# MSPM0L134X register map
Vendor: Texas Instruments; File version: This preliminary header file does not have a version number - build date: 2023-02-21 16:43:37
CPU: CM0 r0p1, little endian, MPU, no FPU, 3 interrupt priority bits
Registers are 32-bit, read-write, reset 0x0 unless marked. A register's access mark holds for its fields unless they carry their own. Offsets are from the block's base; [hi:lo] are bit positions; lines under a group give offsets from that group; {n}, {i} and the like mark numbered series.

## FLASHCTL — F65NW
Base 0x400CD000
0x1020 IIDX ro — Interrupt Index Register
  [0] IIDX_STAT — Indicates which interrupt has fired. 0x0 means no event pending. The priority order is fixed. On each read, only one interrupt is indicated. On a read, the current interrupt (highest priority) is automatically cleared by the hardware and the corresponding interrupt flags in the RIS and MIS are cleared as well. After a read from the CPU (not from the debug interface), the register must be updated with the next highest priority interrupt.
    0=IIDX_STAT_NO_INTR (NO_INTR); 1=IIDX_STAT_DONE (DONE)
0x1028 IMASK — Interrupt Mask Register
  [0] IMASK_DONE — Interrupt mask for DONE: 0: Interrupt is disabled in MIS register 1: Interrupt is enabled in MIS register
    0=IMASK_DONE_DISABLED (DISABLED); 1=IMASK_DONE_ENABLED (ENABLED)
0x1030 RIS ro — Raw Interrupt Status Register
  [0] RIS_DONE — NoWrapper operation completed. This interrupt bit is set by firmware or the corresponding bit in the ISET register. It is cleared by the corresponding bit in in the ICLR register or reading the IIDX register when this interrupt is the highest priority.
    0=RIS_DONE_CLR (CLR); 1=RIS_DONE_SET (SET)
0x1038 MIS ro — Masked Interrupt Status Register
  [0] MIS_DONE — NoWrapper operation completed. This masked interrupt bit reflects the bitwise AND of the corresponding RIS and IMASK bits.
    0=MIS_DONE_CLR (CLR); 1=MIS_DONE_SET (SET)
0x1040 ISET wo — Interrupt Set Register
  [0] ISET_DONE — 0: No effect 1: Set the DONE interrupt in the RIS register
    0=ISET_DONE_NO_EFFECT (NO_EFFECT); 1=ISET_DONE_SET (SET)
0x1048 ICLR wo — Interrupt Clear Register
  [0] ICLR_DONE — 0: No effect 1: Clear the DONE interrupt in the RIS register
    0=ICLR_DONE_NO_EFFECT (NO_EFFECT); 1=ICLR_DONE_CLR (CLR)
0x10E0 EVT_MODE ro — Event Mode
  [1:0] EVT_MODE_INT0_CFG — Event line mode select for peripheral event
    0=EVT_MODE_INT0_CFG_DISABLE (DISABLE); 1=EVT_MODE_INT0_CFG_SOFTWARE (SOFTWARE); 2=EVT_MODE_INT0_CFG_HARDWARE (HARDWARE)
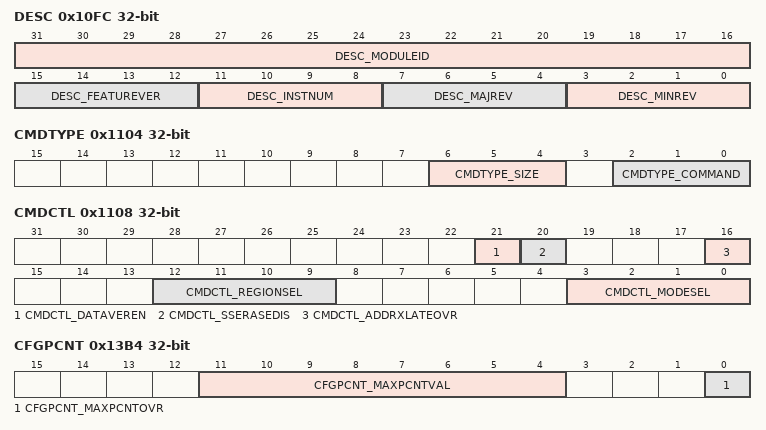
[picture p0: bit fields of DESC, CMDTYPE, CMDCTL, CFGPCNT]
0x10FC DESC ro — Hardware Version Description Register
  [31:16] DESC_MODULEID — Module ID
  [15:12] DESC_FEATUREVER — Feature set
  [11:8] DESC_INSTNUM — Instance number
  [7:4] DESC_MAJREV — Major Revision
  [3:0] DESC_MINREV — Minor Revision
0x1100 CMDEXEC — Command Execute Register
  [0] CMDEXEC_VAL — Command Execute value Initiates execution of the command specified in the CMDTYPE register.
    0=CMDEXEC_VAL_NOEXECUTE (NOEXECUTE); 1=CMDEXEC_VAL_EXECUTE (EXECUTE)
0x1104 CMDTYPE — Command Type Register
  [6:4] CMDTYPE_SIZE — Command size
    0=CMDTYPE_SIZE_ONEWORD (ONEWORD); 1=CMDTYPE_SIZE_TWOWORD (TWOWORD); 2=CMDTYPE_SIZE_FOURWORD (FOURWORD); 3=CMDTYPE_SIZE_EIGHTWORD (EIGHTWORD); 4=CMDTYPE_SIZE_SECTOR (SECTOR); 5=CMDTYPE_SIZE_BANK (BANK)
  [2:0] CMDTYPE_COMMAND — Command type
    0=CMDTYPE_COMMAND_NOOP (NOOP); 1=CMDTYPE_COMMAND_PROGRAM (PROGRAM); 2=CMDTYPE_COMMAND_ERASE (ERASE); 3=CMDTYPE_COMMAND_READVERIFY (READVERIFY); 4=CMDTYPE_COMMAND_MODECHANGE (MODECHANGE); 5=CMDTYPE_COMMAND_CLEARSTATUS (CLEARSTATUS); 6=CMDTYPE_COMMAND_BLANKVERIFY (BLANKVERIFY)
0x1108 CMDCTL — Command Control Register
  [21] CMDCTL_DATAVEREN — Enable invalid data verify. This checks for 0->1 transitions in the memory when a program operation is initiated. If such a transition is found, the program will fail with an error without doing any programming.
    0=CMDCTL_DATAVEREN_DISABLE (DISABLE); 1=CMDCTL_DATAVEREN_ENABLE (ENABLE)
  [20] CMDCTL_SSERASEDIS — Disable Stair-Step Erase. If set, the default VHV trim voltage setting will be used for all erase pulses. By default, this bit is reset, meaning that the VHV voltage will be stepped during successive erase pulses. The step count, step voltage, begin and end voltages are all hard-wired.
    0=CMDCTL_SSERASEDIS_ENABLE (ENABLE); 1=CMDCTL_SSERASEDIS_DISABLE (DISABLE)
  [16] CMDCTL_ADDRXLATEOVR — Override hardware address translation of address in CMDADDR from a system address to a bank address and bank ID. Use data written to CMDADDR directly as the bank address. Use the value written to CMDCTL.BANKSEL directly as the bank ID. Use the value written to CMDCTL.REGIONSEL directly as the region ID.
    0=CMDCTL_ADDRXLATEOVR_NOOVERRIDE (NOOVERRIDE); 1=CMDCTL_ADDRXLATEOVR_OVERRIDE (OVERRIDE)
  [12:9] CMDCTL_REGIONSEL — Bank Region A specific region ID can be written to this field to indicate to which region an operation should be applied if CMDCTL.ADDRXLATEOVR is set.
    1=CMDCTL_REGIONSEL_MAIN (MAIN); 2=CMDCTL_REGIONSEL_NONMAIN (NONMAIN); 4=CMDCTL_REGIONSEL_TRIM (TRIM); 8=CMDCTL_REGIONSEL_ENGR (ENGR)
  [3:0] CMDCTL_MODESEL — Mode This field is only used for the Mode Change command type. Otherwise, bank and pump modes are set automaticlly via the NW hardware.
    0=CMDCTL_MODESEL_READ (READ); 2=CMDCTL_MODESEL_RDMARG0 (RDMARG0); 4=CMDCTL_MODESEL_RDMARG1 (RDMARG1); 6=CMDCTL_MODESEL_RDMARG0B (RDMARG0B); 7=CMDCTL_MODESEL_RDMARG1B (RDMARG1B); 9=CMDCTL_MODESEL_PGMVER (PGMVER); 10=CMDCTL_MODESEL_PGMSW (PGMSW); 11=CMDCTL_MODESEL_ERASEVER (ERASEVER); 12=CMDCTL_MODESEL_ERASESECT (ERASESECT); 14=CMDCTL_MODESEL_PGMMW (PGMMW); 15=CMDCTL_MODESEL_ERASEBNK (ERASEBNK)
0x1120 CMDADDR — Command Address Register
  [31:0] CMDADDR_VAL — Address value
0x1124 CMDBYTEN — Command Program Byte Enable Register
  [7:0] CMDBYTEN_VAL — Command Byte Enable value. A 1-bit per flash word byte value is placed in this register.
0x1130 CMDDATA0 — Command Data Register 0
  [31:0] CMDDATA0_VAL — A 32-bit data value is placed in this field.
0x1134 CMDDATA1 — Command Data Register 1
  [31:0] CMDDATA1_VAL — A 32-bit data value is placed in this field.
0x11D0 CMDWEPROTA — Command Write Erase Protect A Register
  [31:0] CMDWEPROTA_VAL — Each bit protects 1 sector. bit [0]: When 1, sector 0 of the flash memory will be protected from program and erase. bit [1]: When 1, sector 1 of the flash memory will be protected from program and erase. : : bit [31]: When 1, sector 31 of the flash memory will be protected from program and erase.
0x11D4 CMDWEPROTB — Command Write Erase Protect B Register
  [3:0] CMDWEPROTB_VAL — Each bit protects a group of 8 sectors. When a bit is 1, the associated 8 sectors in the flash will be protected from program and erase. A maximum of 256 sectors can be protected with this register.
0x11D8 CMDWEPROTC — Command Write Erase Protect C Register
  [0] CMDWEPROTC_VAL — Each bit protects a group of 8 sectors. When a bit is 1, the associated 8 sectors in the flash will be protected from program and erase. Note that the sectors protected with this register start at sector 256 in the flash, where the sectors protected by the CMDWEPROTB register end.
0x1210 CMDWEPROTNM — Command Write Erase Protect Non-Main Register
  [0] CMDWEPROTNM_VAL — Each bit protects 1 sector. bit [0]: When 1, sector 0 of the non-main region will be protected from program and erase. bit [1]: When 1, sector 1 of the non-main region will be protected from program and erase. : : bit [31]: When 1, sector 31 of the non-main will be protected from program and erase.
0x1214 CMDWEPROTTR — Command Write Erase Protect Trim Register
  [0] CMDWEPROTTR_VAL — Each bit protects 1 sector. bit [0]: When 1, sector 0 of the engr region will be protected from program and erase. bit [1]: When 1, sector 1 of the engr region will be protected from program and erase. : : bit [31]: When 1, sector 31 of the engr region will be protected from program and erase.
0x1218 CMDWEPROTEN — Command Write Erase Protect Engr Register
  [1:0] CMDWEPROTEN_VAL — Each bit protects 1 sector. bit [0]: When 1, sector 0 of the engr region will be protected from program and erase. bit [1]: When 1, sector 1 of the engr region will be protected from program and erase. : : bit [31]: When 1, sector 31 of the engr region will be protected from program and erase.
0x13B0 CFGCMD — Command Configuration Register
  [3:0] CFGCMD_WAITSTATE — Wait State setting for program verify, erase verify and read verify
0x13B4 CFGPCNT — Pulse Counter Configuration Register
  [11:4] CFGPCNT_MAXPCNTVAL — Override maximum pulse counter with this value. If MAXPCNTOVR = 0, then this field is ignored. If MAXPCNTOVR = 1 and MAXERSPCNTOVR = 0, then this value will be used to override the max pulse count for both program and erase. Full max value will be {4'h0, MAXPCNTVAL} . If MAXPCNTOVR = 1 and MAXERSPCNTOVR = 1, then this value will be used to override the max pulse count for program only. Full max value will be {4'h0, MAXPCNTVAL}.
  [0] CFGPCNT_MAXPCNTOVR — Override hard-wired maximum pulse count. If MAXERSPCNTOVR is not set, then setting this value alone will override the max pulse count for both program and erase. If MAXERSPCNTOVR is set, then this bit will only control the max pulse count setting for program. By default, this bit is 0, and a hard-wired max pulse count is used.
    0=CFGPCNT_MAXPCNTOVR_DEFAULT (DEFAULT); 1=CFGPCNT_MAXPCNTOVR_OVERRIDE (OVERRIDE)
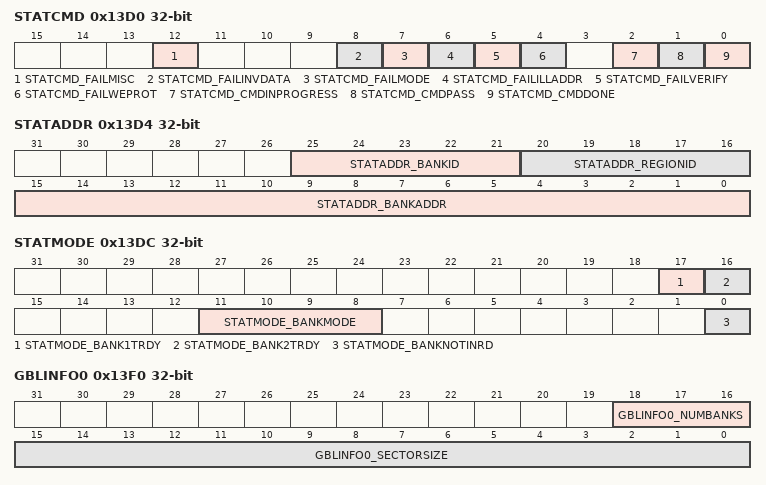
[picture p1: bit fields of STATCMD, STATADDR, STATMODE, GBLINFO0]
0x13D0 STATCMD ro — Command Status Register
  [12] STATCMD_FAILMISC — Command failed due to error other than write/erase protect violation or verify error. This is an extra bit in case a new failure mechanism is added which requires a status bit.
    0=STATCMD_FAILMISC_STATNOFAIL (STATNOFAIL); 1=STATCMD_FAILMISC_STATFAIL (STATFAIL)
  [8] STATCMD_FAILINVDATA — Program command failed because an attempt was made to program a stored 0 value to a 1.
    0=STATCMD_FAILINVDATA_STATNOFAIL (STATNOFAIL); 1=STATCMD_FAILINVDATA_STATFAIL (STATFAIL)
  [7] STATCMD_FAILMODE — Command failed because a bank has been set to a mode other than READ. Program and Erase commands cannot be initiated unless all banks are in READ mode.
    0=STATCMD_FAILMODE_STATNOFAIL (STATNOFAIL); 1=STATCMD_FAILMODE_STATFAIL (STATFAIL)
  [6] STATCMD_FAILILLADDR — Command failed due to the use of an illegal address
    0=STATCMD_FAILILLADDR_STATNOFAIL (STATNOFAIL); 1=STATCMD_FAILILLADDR_STATFAIL (STATFAIL)
  [5] STATCMD_FAILVERIFY — Command failed due to verify error
    0=STATCMD_FAILVERIFY_STATNOFAIL (STATNOFAIL); 1=STATCMD_FAILVERIFY_STATFAIL (STATFAIL)
  [4] STATCMD_FAILWEPROT — Command failed due to Write/Erase Protect Sector Violation
    0=STATCMD_FAILWEPROT_STATNOFAIL (STATNOFAIL); 1=STATCMD_FAILWEPROT_STATFAIL (STATFAIL)
  [2] STATCMD_CMDINPROGRESS — Command In Progress
    0=STATCMD_CMDINPROGRESS_STATCOMPLETE (STATCOMPLETE); 1=STATCMD_CMDINPROGRESS_STATINPROGRESS (STATINPROGRESS)
  [1] STATCMD_CMDPASS — Command Pass - valid when CMD_DONE field is 1
    0=STATCMD_CMDPASS_STATFAIL (STATFAIL); 1=STATCMD_CMDPASS_STATPASS (STATPASS)
  [0] STATCMD_CMDDONE — Command Done
    0=STATCMD_CMDDONE_STATNOTDONE (STATNOTDONE); 1=STATCMD_CMDDONE_STATDONE (STATDONE)
0x13D4 STATADDR ro — Address Status Register
  [25:21] STATADDR_BANKID — Current Bank ID A bank indicator is stored in this register which represents the current bank on which the state machine is operating. There is 1 bit per bank.
    1=STATADDR_BANKID_BANK0 (BANK0); 2=STATADDR_BANKID_BANK1 (BANK1); 4=STATADDR_BANKID_BANK2 (BANK2); 8=STATADDR_BANKID_BANK3 (BANK3); 16=STATADDR_BANKID_BANK4 (BANK4)
  [20:16] STATADDR_REGIONID — Current Region ID A region indicator is stored in this register which represents the current flash region on which the state machine is operating.
    1=STATADDR_REGIONID_MAIN (MAIN); 2=STATADDR_REGIONID_NONMAIN (NONMAIN); 4=STATADDR_REGIONID_TRIM (TRIM); 8=STATADDR_REGIONID_ENGR (ENGR)
  [15:0] STATADDR_BANKADDR — Current Bank Address A bank offset address is stored in this register.
0x13D8 STATPCNT ro — Pulse Count Status Register
  [11:0] STATPCNT_PULSECNT — Current Pulse Counter Value
0x13DC STATMODE ro — Mode Status Register
  [17] STATMODE_BANK1TRDY — Bank 1T Ready. Bank(s) are ready for 1T access. This is accomplished when the bank and pump have been trimmed.
    0=STATMODE_BANK1TRDY_FALSE (FALSE); 1=STATMODE_BANK1TRDY_TRUE (TRUE)
  [16] STATMODE_BANK2TRDY — Bank 2T Ready. Bank(s) are ready for 2T access. This is accomplished when the pump has fully driven power rails to the bank(s).
    0=STATMODE_BANK2TRDY_FALSE (FALSE); 1=STATMODE_BANK2TRDY_TRUE (TRUE)
  [11:8] STATMODE_BANKMODE — Indicates mode of bank(s) that are not in READ mode
    0=STATMODE_BANKMODE_READ (READ); 2=STATMODE_BANKMODE_RDMARG0 (RDMARG0); 4=STATMODE_BANKMODE_RDMARG1 (RDMARG1); 6=STATMODE_BANKMODE_RDMARG0B (RDMARG0B); 7=STATMODE_BANKMODE_RDMARG1B (RDMARG1B); 9=STATMODE_BANKMODE_PGMVER (PGMVER); 10=STATMODE_BANKMODE_PGMSW (PGMSW); 11=STATMODE_BANKMODE_ERASEVER (ERASEVER); 12=STATMODE_BANKMODE_ERASESECT (ERASESECT); 14=STATMODE_BANKMODE_PGMMW (PGMMW); 15=STATMODE_BANKMODE_ERASEBNK (ERASEBNK)
  [0] STATMODE_BANKNOTINRD — Bank not in read mode. Indicates which banks are not in READ mode. There is 1 bit per bank.
    1=STATMODE_BANKNOTINRD_BANK0 (BANK0); 2=STATMODE_BANKNOTINRD_BANK1 (BANK1); 4=STATMODE_BANKNOTINRD_BANK2 (BANK2); 8=STATMODE_BANKNOTINRD_BANK3 (BANK3); 16=STATMODE_BANKNOTINRD_BANK4 (BANK4)
0x13F0 GBLINFO0 ro — Global Information Register 0
  [18:16] GBLINFO0_NUMBANKS — Number of banks instantiated Minimum: 1 Maximum: 5
  [15:0] GBLINFO0_SECTORSIZE — Sector size in bytes
    0x400=GBLINFO0_SECTORSIZE_ONEKB (ONEKB); 0x800=GBLINFO0_SECTORSIZE_TWOKB (TWOKB)
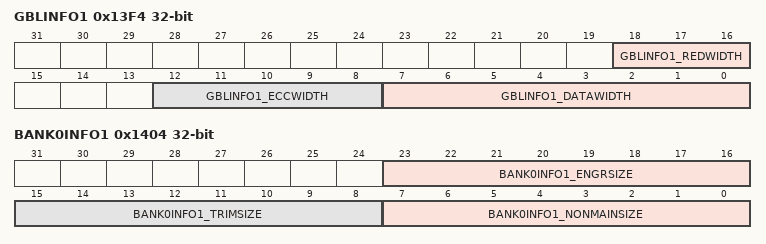
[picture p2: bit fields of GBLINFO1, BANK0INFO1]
0x13F4 GBLINFO1 ro — Global Information Register 1
  [18:16] GBLINFO1_REDWIDTH — Redundant data width in bits
    0=GBLINFO1_REDWIDTH_W0BIT (W0BIT); 2=GBLINFO1_REDWIDTH_W2BIT (W2BIT); 4=GBLINFO1_REDWIDTH_W4BIT (W4BIT)
  [12:8] GBLINFO1_ECCWIDTH — ECC data width in bits
    0=GBLINFO1_ECCWIDTH_W0BIT (W0BIT); 8=GBLINFO1_ECCWIDTH_W8BIT (W8BIT); 16=GBLINFO1_ECCWIDTH_W16BIT (W16BIT)
  [7:0] GBLINFO1_DATAWIDTH — Data width in bits
    64=GBLINFO1_DATAWIDTH_W64BIT (W64BIT); 128=GBLINFO1_DATAWIDTH_W128BIT (W128BIT)
0x13F8 GBLINFO2 ro — Global Information Register 2
  [3:0] GBLINFO2_DATAREGISTERS — Number of data registers present.
0x1400 BANK0INFO0 ro — Bank Information Register 0 for Bank 0
  [11:0] BANK0INFO0_MAINSIZE — Main region size in sectors Minimum: 0x8 (8) Maximum: 0x200 (512)
    8=BANK0INFO0_MAINSIZE_MINSECTORS (MINSECTORS); 0x200=BANK0INFO0_MAINSIZE_MAXSECTORS (MAXSECTORS)
0x1404 BANK0INFO1 ro — Bank Information Register 1 for Bank 0
  [23:16] BANK0INFO1_ENGRSIZE — Engr region size in sectors Minimum: 0x0 (0) Maximum: 0x10 (16)
    0=BANK0INFO1_ENGRSIZE_MINSECTORS (MINSECTORS); 32=BANK0INFO1_ENGRSIZE_MAXSECTORS (MAXSECTORS)
  [15:8] BANK0INFO1_TRIMSIZE — Trim region size in sectors Minimum: 0x0 (0) Maximum: 0x10 (16)
    0=BANK0INFO1_TRIMSIZE_MINSECTORS (MINSECTORS); 32=BANK0INFO1_TRIMSIZE_MAXSECTORS (MAXSECTORS)
  [7:0] BANK0INFO1_NONMAINSIZE — Non-main region size in sectors Minimum: 0x0 (0) Maximum: 0x10 (16)
    0=BANK0INFO1_NONMAINSIZE_MINSECTORS (MINSECTORS); 32=BANK0INFO1_NONMAINSIZE_MAXSECTORS (MAXSECTORS)
